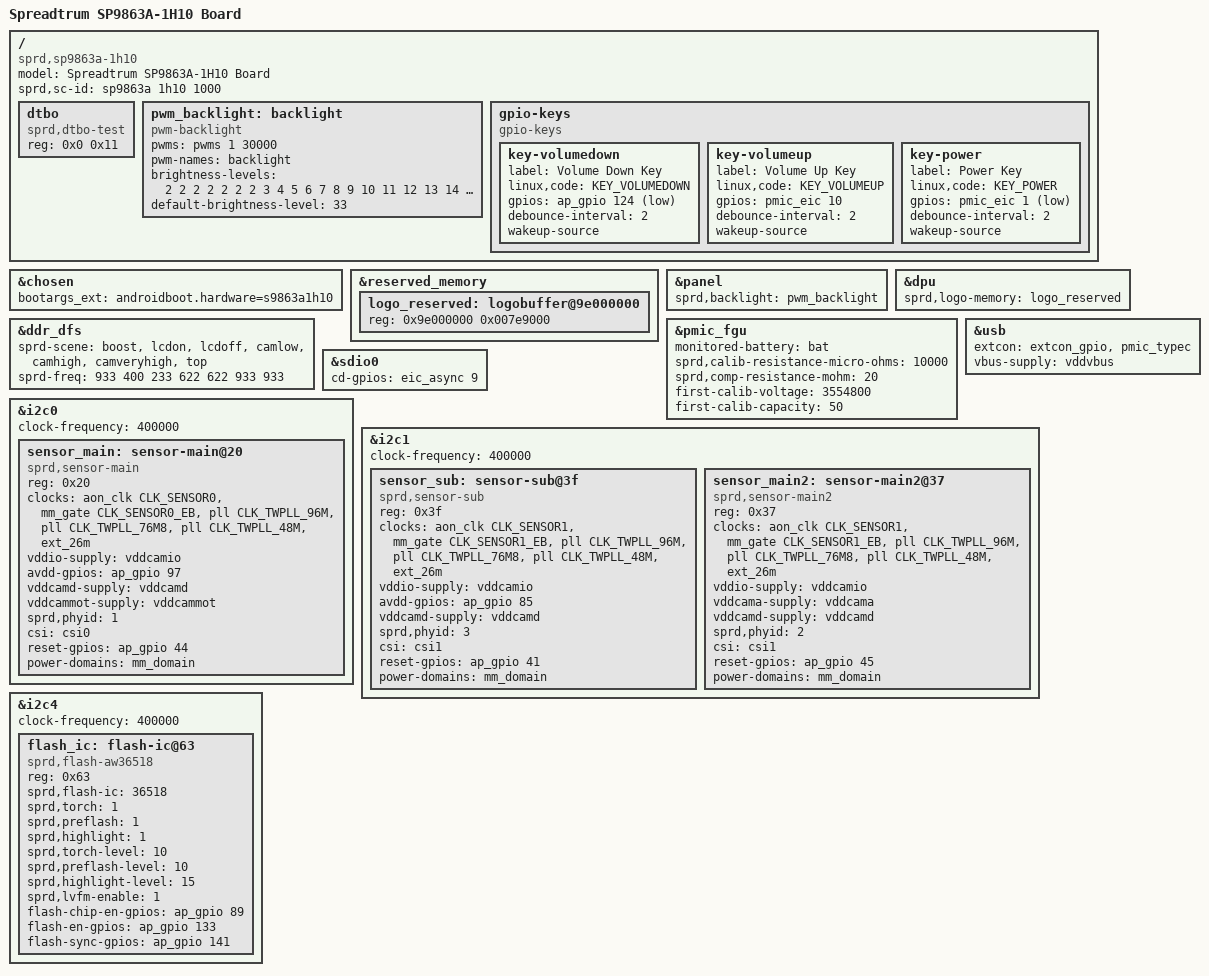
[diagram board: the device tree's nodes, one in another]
/dts-v1/;
/plugin/;
#include <dt-bindings/input/input.h>
#include <dt-bindings/gpio/gpio.h>
#include <dt-bindings/clock/sprd,sc9863a-clk.h>
#include "../lcd/lcd_nt35695_truly_mipi_fhd.dtsi"
#include "../lcd/lcd_nt35532_truly_mipi_fhd.dtsi"
#include "../lcd/lcd_nt35596_boe_mipi_fhd.dtsi"
#include "../lcd/lcd_dummy_mipi.dtsi"

/ {
	model = "Spreadtrum SP9863A-1H10 Board";

	compatible = "sprd,sp9863a-1h10", "sprd,sc9863a";

	sprd,sc-id = "sp9863a 1h10 1000";

	fragment {
		target-path = "/";
		__overlay__ {
			#address-cells = <1>;
			#size-cells = <1>;
			dtbo: dtbo {
				compatible = "sprd,dtbo-test";
				reg = <0x0 0x11>;
			};

			pwm_backlight: backlight {
				compatible = "pwm-backlight";
				pwms = <&pwms 1 30000>;
				pwm-names = "backlight";
				brightness-levels = <
								  2   2   2   2
					  2   2   2   3   4   5   6   7   8   9
					 10  11  12  13  14  15  16  17  18  19
					 20  21  22  23  24  25  26  27  28  29
					 30  31  32  33  34  35  36  37  38  39
					 40  41  42  43  44  45  46  47  48  49
					 50  51  52  53  54  55  56  57  58  59
					 60  61  62  63  64  65  66  67  68  69
					 70  71  72  73  74  75  76  77  78  79
					 80  81  82  83  84  85  86  87  88  89
					 90  91  92  93  94  95  96  97  98  99
					100 101 102 103 104 105 106 107 108 109
					110 111 112 113 114 115 116 117 118 119
					120 121 122 123 124 125 126 127 128 129
					130 131 132 133 134 135 136 137 138 139
					140 141 142 143 144 145 146 147 148 149
					150 151 152 153 154 155 156 157 158 159
					160 161 162 163 164 165 166 167 168 169
					170 171 172 173 174 175 176 177 178 179
					180 181 182 183 184 185 186 187 188 189
					190 191 192 193 194 195 196 197 198 199
					200 201 202 203 204 205 206 207 208 209
					210 211 212 213 214 215 216 217 218 219
					220 221 222 223 224 225 226 227 228 229
					230 231 232 233 234 235 236 237 238 239
					240 241 242 243 244 245 246 247 248 249
					250 251
				>;
				default-brightness-level = <33>;
			};
		
			gpio-keys {
				compatible = "gpio-keys";
				key-volumedown {
					label = "Volume Down Key";
					linux,code = <KEY_VOLUMEDOWN>;
					gpios = <&ap_gpio 124 GPIO_ACTIVE_LOW>;
					debounce-interval = <2>;
					wakeup-source;
				};
				key-volumeup {
					label = "Volume Up Key";
					linux,code = <KEY_VOLUMEUP>;
					gpios = <&pmic_eic 10 GPIO_ACTIVE_HIGH>;
					debounce-interval = <2>;
					wakeup-source;
				};
				key-power {
					label = "Power Key";
					linux,code =<KEY_POWER>;
					gpios = <&pmic_eic 1 GPIO_ACTIVE_LOW>;
					debounce-interval = <2>;
					wakeup-source;
				};
			};
		};
	};
};

&chosen {
	bootargs_ext = "androidboot.hardware=s9863a1h10";
};

&reserved_memory {
	#address-cells = <1>;
	#size-cells = <1>;

	logo_reserved: logobuffer@9e000000{
		reg = <0x9e000000 0x007e9000>;
	};
};
&panel {
	sprd,backlight = <&pwm_backlight>;
};
&dpu {
	sprd,logo-memory = <&logo_reserved>;
};

&ddr_dfs {
	sprd-scene = "boost", "lcdon", "lcdoff", "camlow",
		"camhigh", "camveryhigh","top";
	sprd-freq = <933 400 233 622 622 933 933>;
};

&pmic_fgu {
      monitored-battery = <&bat>;
       sprd,calib-resistance-micro-ohms = <10000>;
       sprd,comp-resistance-mohm = <20>;
       first-calib-voltage = <3554800>;
       first-calib-capacity = <50>;
};

&usb{
	extcon = <&extcon_gpio>, <&pmic_typec>;
	status = "okay";
	vbus-supply = <&vddvbus>;
};

&sdio0 {
	cd-gpios = <&eic_async 9 0>;
};

&i2c0 {
	#address-cells = <1>;
	#size-cells = <0>;
	status = "okay";
	clock-frequency = <400000>;

	sensor_main: sensor-main@20 {
		compatible = "sprd,sensor-main";
		reg = <0x20>;
		clock-names = "clk_src","sensor_eb",
			"clk_96m","clk_76m8",
			"clk_48m","clk_26m";
		clocks = <&aon_clk CLK_SENSOR0>, <&mm_gate CLK_SENSOR0_EB>,
			<&pll CLK_TWPLL_96M>,<&pll CLK_TWPLL_76M8>,
			<&pll CLK_TWPLL_48M>,<&ext_26m>;
		vddio-supply = <&vddcamio>;
		avdd-gpios=<&ap_gpio 97 0>;
		vddcamd-supply = <&vddcamd>;
		vddcammot-supply = <&vddcammot>;
		sprd,phyid = <1>;
		csi = <&csi0>;
		reset-gpios = <&ap_gpio 44 0>;
		//power-down-gpios = <&ap_gpio 46 0>;
		power-domains = <&mm_domain>;
	};
};

&i2c1 {
	#address-cells = <1>;
	#size-cells = <0>;
	status = "okay";
	clock-frequency = <400000>;

	sensor_sub: sensor-sub@3f {
		compatible = "sprd,sensor-sub";
		reg = <0x3f>;
		clock-names = "clk_src","sensor_eb",
			"clk_96m","clk_76m8",
			"clk_48m","clk_26m";
		clocks = <&aon_clk CLK_SENSOR1>, <&mm_gate CLK_SENSOR1_EB>,
			<&pll CLK_TWPLL_96M>,<&pll CLK_TWPLL_76M8>,
			<&pll CLK_TWPLL_48M>,<&ext_26m>;
		vddio-supply = <&vddcamio>;
		avdd-gpios=<&ap_gpio 85 0>;
		vddcamd-supply = <&vddcamd>;
		sprd,phyid = <3>;
		csi = <&csi1>;
		reset-gpios = <&ap_gpio 41 0>;
		//power-down-gpios = <&ap_gpio 40 0>;
		power-domains = <&mm_domain>;
	};

	sensor_main2: sensor-main2@37 {
		compatible = "sprd,sensor-main2";
		reg = <0x37>;
		clock-names = "clk_src","sensor_eb",
			"clk_96m","clk_76m8",
			"clk_48m","clk_26m";
		clocks = <&aon_clk CLK_SENSOR1>, <&mm_gate CLK_SENSOR1_EB>,
			<&pll CLK_TWPLL_96M>,<&pll CLK_TWPLL_76M8>,
			<&pll CLK_TWPLL_48M>,<&ext_26m>;
		vddio-supply = <&vddcamio>;
		vddcama-supply = <&vddcama>;
		vddcamd-supply = <&vddcamd>;
		sprd,phyid = <2>;
		csi = <&csi1>;
		reset-gpios = <&ap_gpio 45 0>;
		//power-down-gpios = <&ap_gpio 47 0>;
		power-domains = <&mm_domain>;
	};
};


&i2c4 {
	#address-cells = <1>;
	#size-cells = <0>;

	status = "okay";
	clock-frequency = <400000>;

	flash_ic: flash-ic@63 {
		compatible = "sprd,flash-aw36518";
		reg = <0x63>;
		sprd,flash-ic = <36518>;
		sprd,torch = <1>;
		sprd,preflash = <1>;
		sprd,highlight = <1>;
		sprd,torch-level = <10>;
		sprd,preflash-level = <10>;
		sprd,highlight-level = <15>;
		sprd,lvfm-enable = <1>;
		flash-chip-en-gpios = <&ap_gpio 89 0>;
		flash-en-gpios = <&ap_gpio 133 0>;
		flash-sync-gpios = <&ap_gpio 141 0>;
	};
	
};
